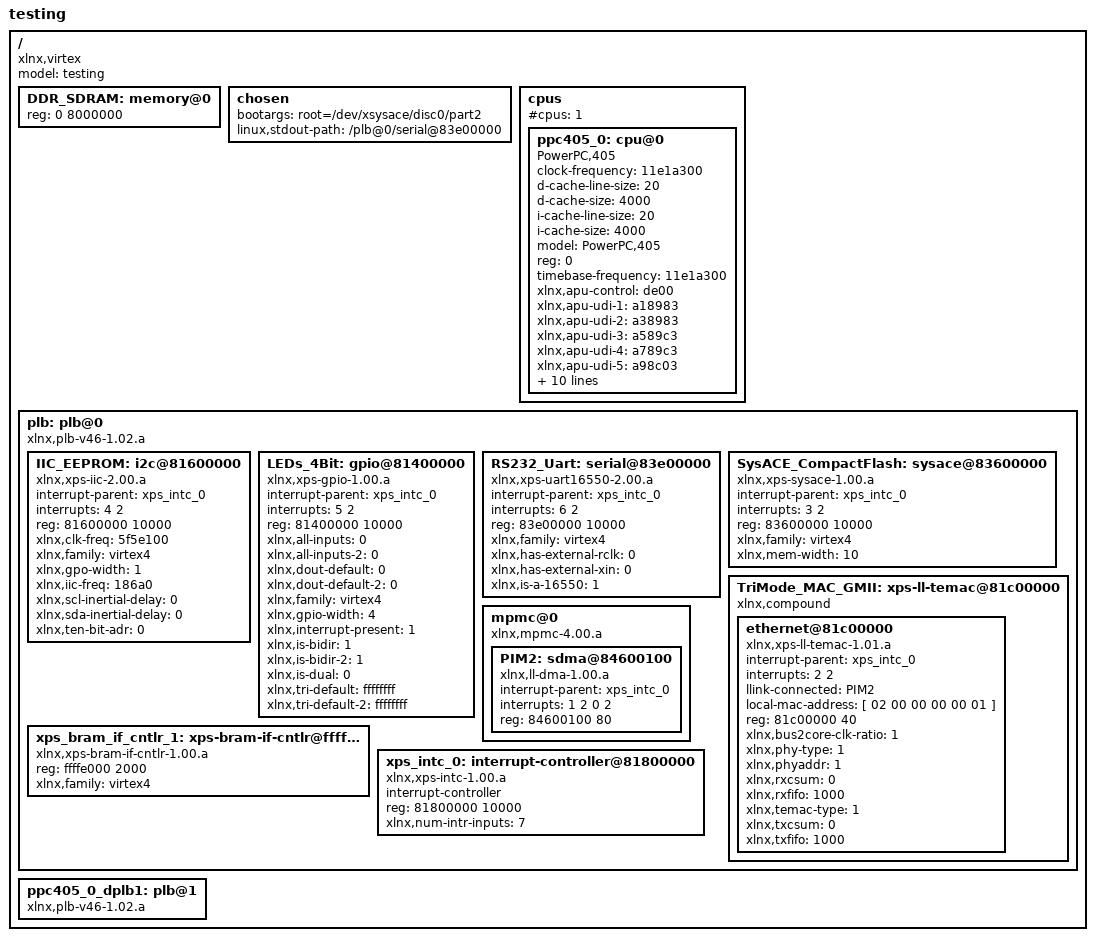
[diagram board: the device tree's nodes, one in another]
/*
 * (C) Copyright 2007 Michal Simek
 *
 * Michal SIMEK <monstr@monstr.eu>
 *
 * This program is free software; you can redistribute it and/or
 * modify it under the terms of the GNU General Public License as
 * published by the Free Software Foundation; either version 2 of
 * the License, or (at your option) any later version.
 *
 * This program is distributed in the hope that it will be useful,
 * but WITHOUT ANY WARRANTY; without even the implied warranty of
 * MERCHANTABILITY or FITNESS FOR A PARTICULAR PURPOSE. See the
 * GNU General Public License for more details.
 *
 * You should have received a copy of the GNU General Public License
 * along with this program; if not, write to the Free Software
 * Foundation, Inc., 59 Temple Place, Suite 330, Boston,
 * MA 02111-1307 USA
 *
 * CAUTION: This file is automatically generated by libgen.
 * Version: Xilinx EDK 10.1.1 EDK_K_SP1.1
 */

/ {
	#address-cells = <1>;
	#size-cells = <1>;
	compatible = "xlnx,virtex";
	model = "testing";
	DDR_SDRAM: memory@0 {
		device_type = "memory";
		reg = < 0 8000000 >;
	} ;
	chosen {
		bootargs = "root=/dev/xsysace/disc0/part2";
		linux,stdout-path = "/plb@0/serial@83e00000";
	} ;
	cpus {
		#address-cells = <1>;
		#cpus = <1>;
		#size-cells = <0>;
		ppc405_0: cpu@0 {
			clock-frequency = <11e1a300>;
			compatible = "PowerPC,405", "ibm,ppc405";
			d-cache-line-size = <20>;
			d-cache-size = <4000>;
			device_type = "cpu";
			i-cache-line-size = <20>;
			i-cache-size = <4000>;
			model = "PowerPC,405";
			reg = <0>;
			timebase-frequency = <11e1a300>;
			xlnx,apu-control = <de00>;
			xlnx,apu-udi-1 = <a18983>;
			xlnx,apu-udi-2 = <a38983>;
			xlnx,apu-udi-3 = <a589c3>;
			xlnx,apu-udi-4 = <a789c3>;
			xlnx,apu-udi-5 = <a98c03>;
			xlnx,apu-udi-6 = <ab8c03>;
			xlnx,apu-udi-7 = <ad8c43>;
			xlnx,apu-udi-8 = <af8c43>;
			xlnx,deterministic-mult = <0>;
			xlnx,disable-operand-forwarding = <1>;
			xlnx,fastest-plb-clock = "DPLB0";
			xlnx,generate-plb-timespecs = <1>;
			xlnx,mmu-enable = <1>;
			xlnx,pvr-high = <0>;
			xlnx,pvr-low = <0>;
		} ;
	} ;
	plb: plb@0 {
		#address-cells = <1>;
		#size-cells = <1>;
		compatible = "xlnx,plb-v46-1.02.a";
		ranges ;
		IIC_EEPROM: i2c@81600000 {
			compatible = "xlnx,xps-iic-2.00.a";
			interrupt-parent = <&xps_intc_0>;
			interrupts = < 4 2 >;
			reg = < 81600000 10000 >;
			xlnx,clk-freq = <5f5e100>;
			xlnx,family = "virtex4";
			xlnx,gpo-width = <1>;
			xlnx,iic-freq = <186a0>;
			xlnx,scl-inertial-delay = <0>;
			xlnx,sda-inertial-delay = <0>;
			xlnx,ten-bit-adr = <0>;
		} ;
		LEDs_4Bit: gpio@81400000 {
			compatible = "xlnx,xps-gpio-1.00.a";
			interrupt-parent = <&xps_intc_0>;
			interrupts = < 5 2 >;
			reg = < 81400000 10000 >;
			xlnx,all-inputs = <0>;
			xlnx,all-inputs-2 = <0>;
			xlnx,dout-default = <0>;
			xlnx,dout-default-2 = <0>;
			xlnx,family = "virtex4";
			xlnx,gpio-width = <4>;
			xlnx,interrupt-present = <1>;
			xlnx,is-bidir = <1>;
			xlnx,is-bidir-2 = <1>;
			xlnx,is-dual = <0>;
			xlnx,tri-default = <ffffffff>;
			xlnx,tri-default-2 = <ffffffff>;
		} ;
		RS232_Uart: serial@83e00000 {
			compatible = "xlnx,xps-uart16550-2.00.a";
			device_type = "serial";
			interrupt-parent = <&xps_intc_0>;
			interrupts = < 6 2 >;
			reg = < 83e00000 10000 >;
			xlnx,family = "virtex4";
			xlnx,has-external-rclk = <0>;
			xlnx,has-external-xin = <0>;
			xlnx,is-a-16550 = <1>;
		} ;
		SysACE_CompactFlash: sysace@83600000 {
			compatible = "xlnx,xps-sysace-1.00.a";
			interrupt-parent = <&xps_intc_0>;
			interrupts = < 3 2 >;
			reg = < 83600000 10000 >;
			xlnx,family = "virtex4";
			xlnx,mem-width = <10>;
		} ;
		TriMode_MAC_GMII: xps-ll-temac@81c00000 {
			#address-cells = <1>;
			#size-cells = <1>;
			compatible = "xlnx,compound";
			ethernet@81c00000 {
				compatible = "xlnx,xps-ll-temac-1.01.a";
				device_type = "network";
				interrupt-parent = <&xps_intc_0>;
				interrupts = < 2 2 >;
				llink-connected = <&PIM2>;
				local-mac-address = [ 02 00 00 00 00 01 ];
				reg = < 81c00000 40 >;
				xlnx,bus2core-clk-ratio = <1>;
				xlnx,phy-type = <1>;
				xlnx,phyaddr = <1>;
				xlnx,rxcsum = <0>;
				xlnx,rxfifo = <1000>;
				xlnx,temac-type = <1>;
				xlnx,txcsum = <0>;
				xlnx,txfifo = <1000>;
			} ;
		} ;
		mpmc@0 {
			#address-cells = <1>;
			#size-cells = <1>;
			compatible = "xlnx,mpmc-4.00.a";
			PIM2: sdma@84600100 {
				compatible = "xlnx,ll-dma-1.00.a";
				interrupt-parent = <&xps_intc_0>;
				interrupts = < 1 2 0 2 >;
				reg = < 84600100 80 >;
			} ;
		} ;
		xps_bram_if_cntlr_1: xps-bram-if-cntlr@ffffe000 {
			compatible = "xlnx,xps-bram-if-cntlr-1.00.a";
			reg = < ffffe000 2000 >;
			xlnx,family = "virtex4";
		} ;
		xps_intc_0: interrupt-controller@81800000 {
			#interrupt-cells = <2>;
			compatible = "xlnx,xps-intc-1.00.a";
			interrupt-controller ;
			reg = < 81800000 10000 >;
			xlnx,num-intr-inputs = <7>;
		} ;
	} ;
	ppc405_0_dplb1: plb@1 {
		#address-cells = <1>;
		#size-cells = <1>;
		compatible = "xlnx,plb-v46-1.02.a";
		ranges ;
	} ;
}  ;
